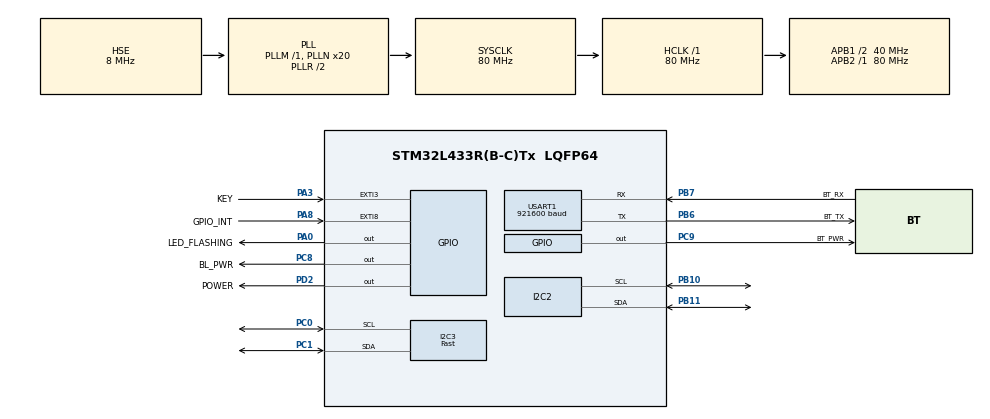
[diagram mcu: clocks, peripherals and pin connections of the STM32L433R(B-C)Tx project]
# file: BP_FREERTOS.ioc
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FREERTOS.INCLUDE_pcTaskGetTaskName=1
FREERTOS.INCLUDE_xEventGroupSetBitFromISR=1
FREERTOS.Tasks01=defaultTask,24,128,StartDefaultTask,Default,NULL,Dynamic,NULL,NULL
FREERTOS.configTOTAL_HEAP_SIZE=20480
FREERTOS.configUSE_IDLE_HOOK=1
FREERTOS.configUSE_STATS_FORMATTING_FUNCTIONS=1
FREERTOS.configUSE_TICK_HOOK=1
I2C2.Timing=0x00909BEB
I2C3.Analog_Filter=I2C_ANALOGFILTER_DISABLE
I2C3.I2C_Fall_Time=100
I2C3.I2C_Rise_Time=100
I2C3.I2C_Speed_Mode=I2C_Fast
I2C3.Timing=0x00701541
Mcu.Family=STM32L4
Mcu.Name=STM32L433R(B-C)Tx
Mcu.Package=LQFP64
NVIC.EXTI3_IRQn=true\:5\:0\:false\:false\:true\:true\:true\:true\:true
NVIC.EXTI9_5_IRQn=true\:5\:0\:false\:false\:true\:true\:true\:true\:true
NVIC.PriorityGroup=NVIC_PRIORITYGROUP_4
NVIC.TIM1_UP_TIM16_IRQn=true\:15\:0\:false\:false\:true\:false\:false\:true\:true
NVIC.TimeBase=TIM1_UP_TIM16_IRQn
NVIC.TimeBaseIP=TIM16
NVIC.USART1_IRQn=true\:5\:0\:false\:false\:true\:true\:true\:true\:true
PA0.GPIO_Label=LED_FLASHING
PA0.GPIO_PuPd=GPIO_PULLUP
PA0.GPIO_Speed=GPIO_SPEED_FREQ_VERY_HIGH
PA0.Signal=GPIO_Output
PA13\ (JTMS-SWDIO).Mode=Serial_Wire
PA13\ (JTMS-SWDIO).Signal=SYS_JTMS-SWDIO
PA14\ (JTCK-SWCLK).Mode=Serial_Wire
PA14\ (JTCK-SWCLK).Signal=SYS_JTCK-SWCLK
PA3.GPIO_Label=KEY
PA3.GPIO_ModeDefaultEXTI=GPIO_MODE_IT_FALLING
PA3.GPIO_PuPd=GPIO_PULLUP
PA3.Signal=GPXTI3
PA8.GPIO_Label=GPIO_INT
PA8.GPIO_ModeDefaultEXTI=GPIO_MODE_IT_FALLING
PA8.GPIO_PuPd=GPIO_PULLUP
PA8.Signal=GPXTI8
PB10.GPIO_Pu=GPIO_PULLUP
PB10.Mode=I2C
PB10.Signal=I2C2_SCL
PB11.GPIO_Pu=GPIO_PULLUP
PB11.Mode=I2C
PB11.Signal=I2C2_SDA
PB6.GPIO_FM6=SYSCFG_FASTMODEPLUS_PB6
PB6.GPIO_Label=BT_TX
PB6.Mode=Asynchronous
PB6.Signal=USART1_TX
PB7.GPIO_FM7=SYSCFG_FASTMODEPLUS_PB7
PB7.GPIO_Label=BT_RX
PB7.Mode=Asynchronous
PB7.Signal=USART1_RX
PC0.GPIO_Pu=GPIO_NOPULL
PC0.Mode=I2C
PC0.Signal=I2C3_SCL
PC1.Mode=I2C
PC1.Signal=I2C3_SDA
PC8.GPIO_Label=BL_PWR
PC8.PinState=GPIO_PIN_SET
PC8.Signal=GPIO_Output
PC9.GPIO_Label=BT_PWR
PC9.PinState=GPIO_PIN_SET
PC9.Signal=GPIO_Output
PD2.GPIO_Label=POWER
PD2.Signal=GPIO_Output
PH0-OSC_IN\ (PH0).Mode=HSE-External-Oscillator
PH0-OSC_IN\ (PH0).Signal=RCC_OSC_IN
PH1-OSC_OUT\ (PH1).Mode=HSE-External-Oscillator
PH1-OSC_OUT\ (PH1).Signal=RCC_OSC_OUT
ProjectManager.HeapSize=0x200
ProjectManager.StackSize=0x400
ProjectManager.TargetToolchain=MDK-ARM V5.32
RCC.ADCFreq_Value=32000000
RCC.AHBFreq_Value=80000000
RCC.APB1CLKDivider=RCC_HCLK_DIV2
RCC.APB1Freq_Value=40000000
RCC.APB1TimFreq_Value=80000000
RCC.APB2Freq_Value=80000000
RCC.APB2TimFreq_Value=80000000
RCC.CortexFreq_Value=80000000
RCC.HCLKFreq_Value=80000000
RCC.HSE_VALUE=8000000
RCC.HSI48_VALUE=48000000
RCC.HSI_VALUE=16000000
RCC.LSE_VALUE=32768
RCC.MSI_VALUE=4000000
RCC.PLLN=20
RCC.PLLSourceVirtual=RCC_PLLSOURCE_HSE
RCC.SYSCLKFreq_VALUE=80000000
RCC.SYSCLKSource=RCC_SYSCLKSOURCE_PLLCLK
RCC.USBFreq_Value=32000000
RCC.VCOOutputFreq_Value=160000000
USART1.BaudRate=921600
USART1.VirtualMode-Asynchronous=VM_ASYNC
VP_FREERTOS_VS_CMSIS_V2.Mode=CMSIS_V2
VP_SYS_VS_tim16.Mode=TIM16
board=custom

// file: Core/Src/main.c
/* USER CODE BEGIN Header */
/**
  ******************************************************************************
  * @file           : main.c
  * @brief          : Main program body
  ******************************************************************************
  * @attention
  *
  * Copyright (c) 2025 STMicroelectronics.
  * All rights reserved.
  *
  * This software is licensed under terms that can be found in the LICENSE file
  * in the root directory of this software component.
  * If no LICENSE file comes with this software, it is provided AS-IS.
  *
  ******************************************************************************
  */
/* USER CODE END Header */
#include "main.h"
#include "cmsis_os.h"
#include "i2c.h"
#include "usart.h"
#include "gpio.h"

/* USER CODE BEGIN Includes */
#include "power.h"
#include "bt.h"
#include "delay.h"
#include <stdio.h>
#include "zsbm800x_drv.h"
/* USER CODE END Includes */

void SystemClock_Config(void);
void MX_FREERTOS_Init(void);

int main(void)
{

  /* MCU Configuration--------------------------------------------------------*/

  /* Reset of all peripherals, Initializes the Flash interface and the Systick. */
  HAL_Init();

  /* Configure the system clock */
  SystemClock_Config();

  /* Initialize all configured peripherals */
  MX_GPIO_Init();
  MX_USART1_UART_Init();
  MX_I2C2_Init();
  MX_I2C3_Init();
  /* USER CODE BEGIN 2 */

	BT_Power_On();
  // PowerOn();

  // ZSBM800X_Init(ECG_PPG_MODE);

  /* USER CODE END 2 */

  /* Init scheduler */
  osKernelInitialize();

  /* Call init function for freertos objects (in freertos.c) */
  MX_FREERTOS_Init();

  /* Start scheduler */
  osKernelStart();

  /* We should never get here as control is now taken by the scheduler */
  /* Infinite loop */
  while (1)
  {

  }
}

void SystemClock_Config(void)
{
  RCC_OscInitTypeDef RCC_OscInitStruct = {0};
  RCC_ClkInitTypeDef RCC_ClkInitStruct = {0};

  /** Configure the main internal regulator output voltage
  */
  if (HAL_PWREx_ControlVoltageScaling(PWR_REGULATOR_VOLTAGE_SCALE1) != HAL_OK)
  {
    Error_Handler();
  }

  /** Initializes the RCC Oscillators according to the specified parameters
  * in the RCC_OscInitTypeDef structure.
  */
  RCC_OscInitStruct.OscillatorType = RCC_OSCILLATORTYPE_HSE;
  RCC_OscInitStruct.HSEState = RCC_HSE_ON;
  RCC_OscInitStruct.PLL.PLLState = RCC_PLL_ON;
  RCC_OscInitStruct.PLL.PLLSource = RCC_PLLSOURCE_HSE;
  RCC_OscInitStruct.PLL.PLLM = 1;
  RCC_OscInitStruct.PLL.PLLN = 20;
  RCC_OscInitStruct.PLL.PLLP = RCC_PLLP_DIV7;
  RCC_OscInitStruct.PLL.PLLQ = RCC_PLLQ_DIV2;
  RCC_OscInitStruct.PLL.PLLR = RCC_PLLR_DIV2;
  if (HAL_RCC_OscConfig(&RCC_OscInitStruct) != HAL_OK)
  {
    Error_Handler();
  }

  /** Initializes the CPU, AHB and APB buses clocks
  */
  RCC_ClkInitStruct.ClockType = RCC_CLOCKTYPE_HCLK|RCC_CLOCKTYPE_SYSCLK
                              |RCC_CLOCKTYPE_PCLK1|RCC_CLOCKTYPE_PCLK2;
  RCC_ClkInitStruct.SYSCLKSource = RCC_SYSCLKSOURCE_PLLCLK;
  RCC_ClkInitStruct.AHBCLKDivider = RCC_SYSCLK_DIV1;
  RCC_ClkInitStruct.APB1CLKDivider = RCC_HCLK_DIV2;
  RCC_ClkInitStruct.APB2CLKDivider = RCC_HCLK_DIV1;

  if (HAL_RCC_ClockConfig(&RCC_ClkInitStruct, FLASH_LATENCY_4) != HAL_OK)
  {
    Error_Handler();
  }
}

void HAL_TIM_PeriodElapsedCallback(TIM_HandleTypeDef *htim)
{
  if (htim->Instance == TIM16) {
    HAL_IncTick();
  }
}

void Error_Handler(void)
{
  __disable_irq();
  while (1)
  {
  }
}

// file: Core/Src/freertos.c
/* USER CODE BEGIN Header */
/**
  ******************************************************************************
  * File Name          : freertos.c
  * Description        : Code for freertos applications
  ******************************************************************************
  * @attention
  *
  * Copyright (c) 2025 STMicroelectronics.
  * All rights reserved.
  *
  * This software is licensed under terms that can be found in the LICENSE file
  * in the root directory of this software component.
  * If no LICENSE file comes with this software, it is provided AS-IS.
  *
  ******************************************************************************
  */
/* USER CODE END Header */

#include "FreeRTOS.h"
#include "task.h"
#include "main.h"
#include "cmsis_os.h"

/* USER CODE BEGIN Includes */
#include "rtos_main.h"
/* USER CODE END Includes */

/* Definitions for defaultTask */
osThreadId_t defaultTaskHandle;
const osThreadAttr_t defaultTask_attributes = {
  .name = "defaultTask",
  .stack_size = 128 * 4,
  .priority = (osPriority_t) osPriorityNormal,
};

void StartDefaultTask(void *argument);

void MX_FREERTOS_Init(void); /* (MISRA C 2004 rule 8.1) */

/* Hook prototypes */
void vApplicationIdleHook(void);
void vApplicationTickHook(void);

/* USER CODE BEGIN 2 */
static signed char pcwriteBuffer[200];
void vApplicationIdleHook( void )
{
   /* vApplicationIdleHook() will only be called if configUSE_IDLE_HOOK is set
   to 1 in FreeRTOSConfig.h. It will be called on each iteration of the idle
   task. It is essential that code added to this hook function never attempts
   to block in any way (for example, call xQueueReceive() with a block time
   specified, or call vTaskDelay()). If the application makes use of the
   vTaskDelete() API function (as this demo application does) then it is also
   important that vApplicationIdleHook() is permitted to return to its calling
   function, because it is the responsibility of the idle task to clean up
   memory allocated by the kernel to any task that has since been deleted. */
  //  vTaskList (pcwriteBuffer);
  //  printf("%s\r\n",pcwriteBuffer);
}
/* USER CODE END 2 */

/* USER CODE BEGIN 3 */
void vApplicationTickHook( void )
{
   /* This function will be called by each tick interrupt if
   configUSE_TICK_HOOK is set to 1 in FreeRTOSConfig.h. User code can be
   added here, but the tick hook is called from an interrupt context, so
   code must not attempt to block, and only the interrupt safe FreeRTOS API
   functions can be used (those that end in FromISR()). */
}
/* USER CODE END 3 */

void MX_FREERTOS_Init(void) {
  /* USER CODE BEGIN Init */
	Queue_init();
  Semaphore_init();
  /* USER CODE END Init */

  /* Create the thread(s) */
  /* creation of defaultTask */
  defaultTaskHandle = osThreadNew(StartDefaultTask, NULL, &defaultTask_attributes);

  /* USER CODE BEGIN RTOS_THREADS */
  /* add threads, ... */
	Soft_init();
  /* USER CODE END RTOS_THREADS */

}

void StartDefaultTask(void *argument)
{
  /* USER CODE BEGIN StartDefaultTask */
  /* Infinite loop */
  for(;;)
  {
    osDelay(500);
  }
  /* USER CODE END StartDefaultTask */
}
